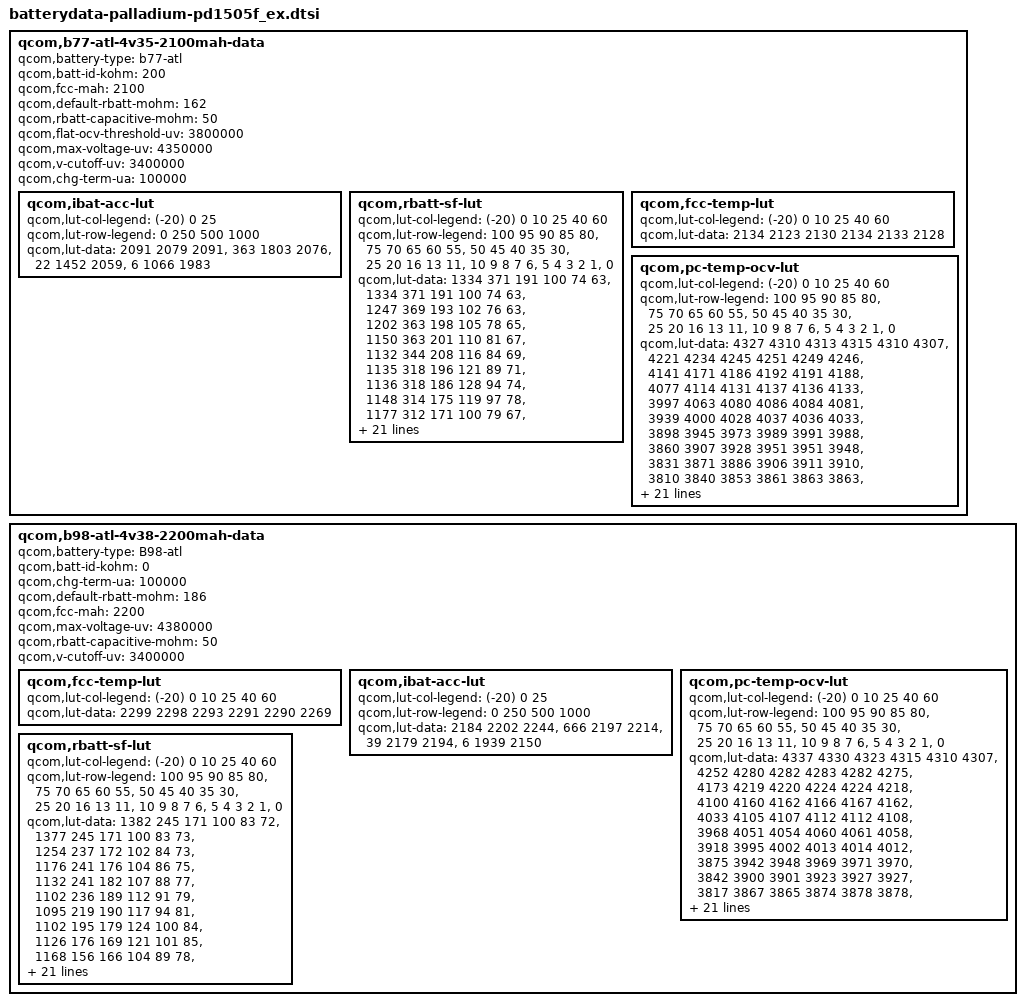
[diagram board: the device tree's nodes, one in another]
/* Copyright (c) 2013-2014, The Linux Foundation. All rights reserved.
 *
 * This program is free software; you can redistribute it and/or modify
 * it under the terms of the GNU General Public License version 2 and
 * only version 2 as published by the Free Software Foundation.
 *
 * This program is distributed in the hope that it will be useful,
 * but WITHOUT ANY WARRANTY; without even the implied warranty of
 * MERCHANTABILITY or FITNESS FOR A PARTICULAR PURPOSE.  See the
 * GNU General Public License for more details.
 */

qcom,b77-atl-4v35-2100mah-data {
	qcom,battery-type = "b77-atl";
	qcom,batt-id-kohm = <200>;
	qcom,fcc-mah = <2100>;
	qcom,default-rbatt-mohm = <162>;
	qcom,rbatt-capacitive-mohm = <50>;
	qcom,flat-ocv-threshold-uv = <3800000>;
	qcom,max-voltage-uv = <4350000>;
	qcom,v-cutoff-uv = <3400000>;
	qcom,chg-term-ua = <100000>;

	qcom,ibat-acc-lut {
		qcom,lut-col-legend = <(-20) 0 25>;
		qcom,lut-row-legend = <0 250 500 1000>;
		qcom,lut-data = <2091 2079 2091>,
				<363 1803 2076>,
				<22 1452 2059>,
				<6 1066 1983>;
	};
	qcom,rbatt-sf-lut {
		qcom,lut-col-legend = <(-20) 0 10 25 40 60>;
		qcom,lut-row-legend = <100 95 90 85 80>,
				<75 70 65 60 55>,
				<50 45 40 35 30>,
				<25 20 16 13 11>,
				<10 9 8 7 6>,
				<5 4 3 2 1>,
				<0>;
		qcom,lut-data = <1334 371 191 100 74 63>,
				<1334 371 191 100 74 63>,
				<1247 369 193 102 76 63>,
				<1202 363 198 105 78 65>,
				<1150 363 201 110 81 67>,
				<1132 344 208 116 84 69>,
				<1135 318 196 121 89 71>,
				<1136 318 186 128 94 74>,
				<1148 314 175 119 97 78>,
				<1177 312 171 100 79 67>,
				<1221 313 171 97 74 64>,
				<1277 319 172 98 75 65>,
				<1348 334 173 101 78 67>,
				<1432 356 180 102 81 70>,
				<1534 385 192 106 80 69>,
				<1677 421 206 108 78 64>,
				<1963 476 220 108 76 64>,
				<2369 547 235 110 78 65>,
				<2673 618 248 109 77 64>,
				<2541 620 254 109 76 64>,
				<2799 649 266 111 78 65>,
				<3131 689 283 115 81 67>,
				<3549 736 304 121 84 68>,
				<4062 788 331 127 87 70>,
				<4736 851 360 134 89 70>,
				<5647 916 392 138 87 68>,
				<6911 995 428 140 87 68>,
				<8815 1100 490 151 92 71>,
				<12604 1269 598 174 102 80>,
				<26360 2997 3364 253 161 141>,
				<26360 2997 3364 253 161 141>;
	};

	qcom,fcc-temp-lut {
		qcom,lut-col-legend = <(-20) 0 10 25 40 60>;
		qcom,lut-data = <2134 2123 2130 2134 2133 2128>;
	};

	qcom,pc-temp-ocv-lut {
		qcom,lut-col-legend = <(-20) 0 10 25 40 60>;
		qcom,lut-row-legend = <100 95 90 85 80>,
				<75 70 65 60 55>,
				<50 45 40 35 30>,
				<25 20 16 13 11>,
				<10 9 8 7 6>,
				<5 4 3 2 1>,
				<0>;
				
		qcom,lut-data =					
		                <4327 4310 4313 4315 4310 4307>,
				<4221 4234 4245 4251 4249 4246>,
				<4141 4171 4186 4192 4191 4188>,
				<4077 4114 4131 4137 4136 4133>,
				<3997 4063 4080 4086 4084 4081>,
				<3939 4000 4028 4037 4036 4033>,
				<3898 3945 3973 3989 3991 3988>,
				<3860 3907 3928 3951 3951 3948>,
				<3831 3871 3886 3906 3911 3910>,
				<3810 3840 3853 3861 3863 3863>,
				<3794 3814 3826 3831 3832 3832>,
				<3781 3794 3804 3809 3810 3809>,
				<3768 3780 3786 3791 3792 3791>,
				<3753 3769 3775 3777 3777 3776>,
				<3738 3757 3765 3767 3763 3758>,
				<3720 3740 3754 3754 3747 3734>,
				<3697 3718 3733 3735 3726 3713>,
				<3676 3701 3710 3711 3702 3691>,
				<3657 3689 3688 3687 3680 3669>,
				<3644 3680 3679 3678 3672 3661>,
				<3634 3674 3675 3675 3670 3659>,
				<3623 3668 3671 3673 3667 3657>,
				<3610 3661 3667 3670 3665 3654>,
				<3593 3652 3662 3665 3660 3650>,
				<3574 3638 3651 3657 3651 3639>,
				<3548 3611 3629 3634 3624 3611>,
				<3514 3567 3585 3590 3576 3562>,
				<3465 3502 3519 3526 3511 3498>,
				<3391 3406 3426 3438 3422 3411>,
				<3271 3248 3283 3304 3285 3271>,
				<3000 3030 3000 3000 3000 3000>;
	};
};

qcom,b98-atl-4v38-2200mah-data {
	qcom,battery-type = "B98-atl";
	qcom,batt-id-kohm = <0>;
	qcom,chg-term-ua = <100000>;
	qcom,default-rbatt-mohm = <186>;
	qcom,fcc-mah = <2200>;
	qcom,max-voltage-uv = <4380000>;
	qcom,rbatt-capacitive-mohm = <50>;
	qcom,v-cutoff-uv = <3400000>;

	qcom,fcc-temp-lut {
		qcom,lut-col-legend = <(-20) 0 10 25 40 60>;
		qcom,lut-data = <2299 2298 2293 2291 2290 2269>;
	};

	qcom,ibat-acc-lut {
		qcom,lut-col-legend = <(-20) 0 25>;
		qcom,lut-row-legend = <0 250 500 1000>;
		qcom,lut-data = <2184 2202 2244>,
				<666 2197 2214>,
				<39 2179 2194>,
				<6 1939 2150>;
	};

	qcom,pc-temp-ocv-lut {
		qcom,lut-col-legend = <(-20) 0 10 25 40 60>;
		qcom,lut-row-legend = <100 95 90 85 80>,
					<75 70 65 60 55>,
					<50 45 40 35 30>,
					<25 20 16 13 11>,
					<10 9 8 7 6>,
					<5 4 3 2 1>,
					<0>;
		qcom,lut-data = <4337 4330 4323 4315 4310 4307>,
				<4252 4280 4282 4283 4282 4275>,
				<4173 4219 4220 4224 4224 4218>,
				<4100 4160 4162 4166 4167 4162>,
				<4033 4105 4107 4112 4112 4108>,
				<3968 4051 4054 4060 4061 4058>,
				<3918 3995 4002 4013 4014 4012>,
				<3875 3942 3948 3969 3971 3970>,
				<3842 3900 3901 3923 3927 3927>,
				<3817 3867 3865 3874 3878 3878>,
				<3795 3839 3836 3842 3845 3845>,
				<3774 3815 3813 3819 3821 3822>,
				<3753 3795 3793 3800 3802 3802>,
				<3732 3779 3777 3784 3785 3786>,
				<3708 3766 3765 3771 3770 3765>,
				<3680 3752 3748 3756 3752 3740>,
				<3643 3727 3721 3733 3731 3718>,
				<3604 3698 3696 3704 3702 3691>,
				<3570 3687 3686 3686 3681 3670>,
				<3542 3682 3681 3683 3678 3668>,
				<3527 3679 3677 3681 3677 3666>,
				<3508 3676 3673 3679 3676 3665>,
				<3486 3671 3667 3677 3674 3663>,
				<3463 3664 3658 3673 3670 3659>,
				<3434 3650 3638 3663 3661 3646>,
				<3401 3619 3606 3636 3631 3611>,
				<3360 3574 3568 3589 3583 3562>,
				<3315 3524 3518 3529 3519 3500>,
				<3266 3445 3434 3447 3433 3418>,
				<3212 3293 3300 3301 3312 3269>,
				<3149 3000 3000 3000 3045 3000>;
	};

	qcom,rbatt-sf-lut {
		qcom,lut-col-legend = <(-20) 0 10 25 40 60>;
		qcom,lut-row-legend = <100 95 90 85 80>,
					<75 70 65 60 55>,
					<50 45 40 35 30>,
					<25 20 16 13 11>,
					<10 9 8 7 6>,
					<5 4 3 2 1>,
					<0>;
		qcom,lut-data = <1382 245 171 100 83 72>,
				<1377 245 171 100 83 73>,
				<1254 237 172 102 84 73>,
				<1176 241 176 104 86 75>,
				<1132 241 182 107 88 77>,
				<1102 236 189 112 91 79>,
				<1095 219 190 117 94 81>,
				<1102 195 179 124 100 84>,
				<1126 176 169 121 101 85>,
				<1168 156 166 104 89 78>,
				<1256 147 168 101 84 75>,
				<1412 148 170 102 86 76>,
				<1611 150 174 105 88 78>,
				<1865 155 181 108 90 81>,
				<2203 161 192 110 89 79>,
				<2685 167 202 110 87 75>,
				<3438 170 209 109 87 75>,
				<4449 166 211 109 87 75>,
				<5235 165 222 106 84 74>,
				<6560 174 242 108 86 76>,
				<7427 181 257 110 88 76>,
				<8632 192 279 113 90 78>,
				<10122 204 305 116 91 78>,
				<12290 223 344 121 92 79>,
				<15327 247 388 125 93 77>,
				<20134 265 456 128 91 77>,
				<27988 314 589 131 93 79>,
				<42305 376 828 140 97 81>,
				<69822 751 1561 155 103 87>,
				<120991 1502 3076 247 121 159>,
				<198255 3005 2391 495 243 317>;
	};
};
